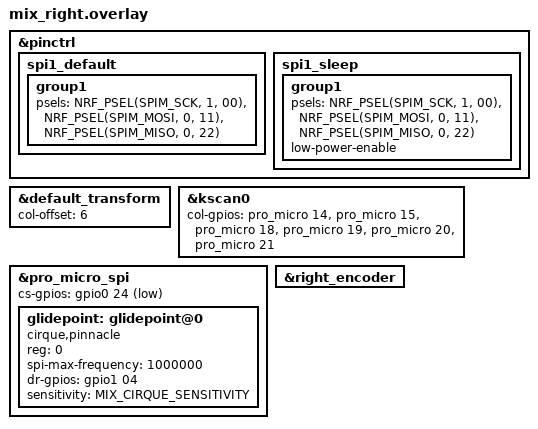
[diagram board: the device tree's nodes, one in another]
/*
 * Copyright (c) 2020 Pete Johanson
 *
 * SPDX-License-Identifier: MIT
 */

#include "mix.dtsi"
#include "../../../config/mix_trackpad_config.dtsi"
#include "mix_trackpad.dtsi"

#include <dt-bindings/zmk/outputs.h>
#include <zephyr/dt-bindings/input/input-event-codes.h>
#include <dt-bindings/zmk/ext_power.h>
#include <dt-bindings/zmk/pointing.h>



&pinctrl {
    /* configuration for spi1 device, default state */
    spi1_default: spi1_default {
        /* node name is arbitrary */
        group1 {
            psels = <NRF_PSEL(SPIM_SCK,  1, 00)>,
                    <NRF_PSEL(SPIM_MOSI, 0, 11)>,
                    <NRF_PSEL(SPIM_MISO, 0, 22)>;
        };
    };

    /* configuration for spi1 device, sleep state */
    spi1_sleep: spi1_sleep {
        group1 {
            psels = <NRF_PSEL(SPIM_SCK, 1, 00)>,
                    <NRF_PSEL(SPIM_MOSI, 0, 11)>,
                    <NRF_PSEL(SPIM_MISO, 0, 22)>;
            low-power-enable;
        };
    };

};




&default_transform {
    col-offset = <6>;
};


&kscan0 {
    col-gpios
        = <&pro_micro 14 GPIO_ACTIVE_HIGH>
        , <&pro_micro 15 GPIO_ACTIVE_HIGH>
        , <&pro_micro 18 GPIO_ACTIVE_HIGH>
        , <&pro_micro 19 GPIO_ACTIVE_HIGH>
        , <&pro_micro 20 GPIO_ACTIVE_HIGH>
        , <&pro_micro 21 GPIO_ACTIVE_HIGH>
        ;
};


&pro_micro_spi {
    status = "okay";
    cs-gpios = <&gpio0 24 GPIO_ACTIVE_LOW>;

    // geeksville/cirque-input-module driver (ZMK v0.3 compatible):
    // https://github.com/geeksville/cirque-input-module
    glidepoint: glidepoint@0 {
        compatible = "cirque,pinnacle";
        reg = <0>;
        spi-max-frequency = <1000000>;
        status = "okay";
        dr-gpios = <&gpio1 04 (GPIO_ACTIVE_HIGH)>;

        // ADC sensitivity: "1x", "2x", "3x", "4x" (driver default "1x"; 1x = most sensitive, 4x = least)
        sensitivity = MIX_CIRQUE_SENSITIVITY;
        // sleep;       // disabled — trackpad stays always-on
        // no-taps;     // disable tap-to-click (taps enabled by default)
    };
};

&right_encoder {
    status = "okay";
};
